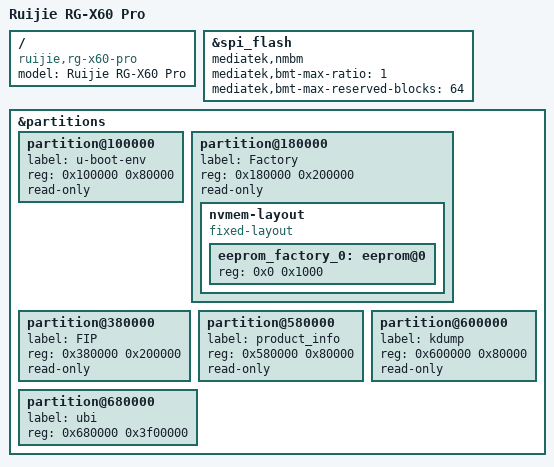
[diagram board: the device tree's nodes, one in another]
// SPDX-License-Identifier: (GPL-2.0 OR MIT)

/dts-v1/;
#include "mt7986a-ruijie-rg-x60-pro-common.dtsi"

/ {
	compatible = "ruijie,rg-x60-pro", "mediatek,mt7986a";
	model = "Ruijie RG-X60 Pro";
};

&spi_flash {
	mediatek,nmbm;
	mediatek,bmt-max-ratio = <1>;
	mediatek,bmt-max-reserved-blocks = <64>;
};

&partitions {
	partition@100000 {
		label = "u-boot-env";
		reg = <0x100000 0x80000>;
		read-only;
	};

	partition@180000 {
		label = "Factory";
		reg = <0x180000 0x200000>;
		read-only;

		nvmem-layout {
			compatible = "fixed-layout";
			#address-cells = <1>;
			#size-cells = <1>;

			eeprom_factory_0: eeprom@0 {
				reg = <0x0 0x1000>;
			};
		};
	};

	partition@380000 {
		label = "FIP";
		reg = <0x380000 0x200000>;
		read-only;
	};

	partition@580000 {
		label = "product_info";
		reg = <0x580000 0x80000>;
		read-only;
	};

	partition@600000 {
		label = "kdump";
		reg = <0x600000 0x80000>;
		read-only;
	};

	partition@680000 {
		label = "ubi";
		reg = <0x680000 0x3f00000>;
	};
};
